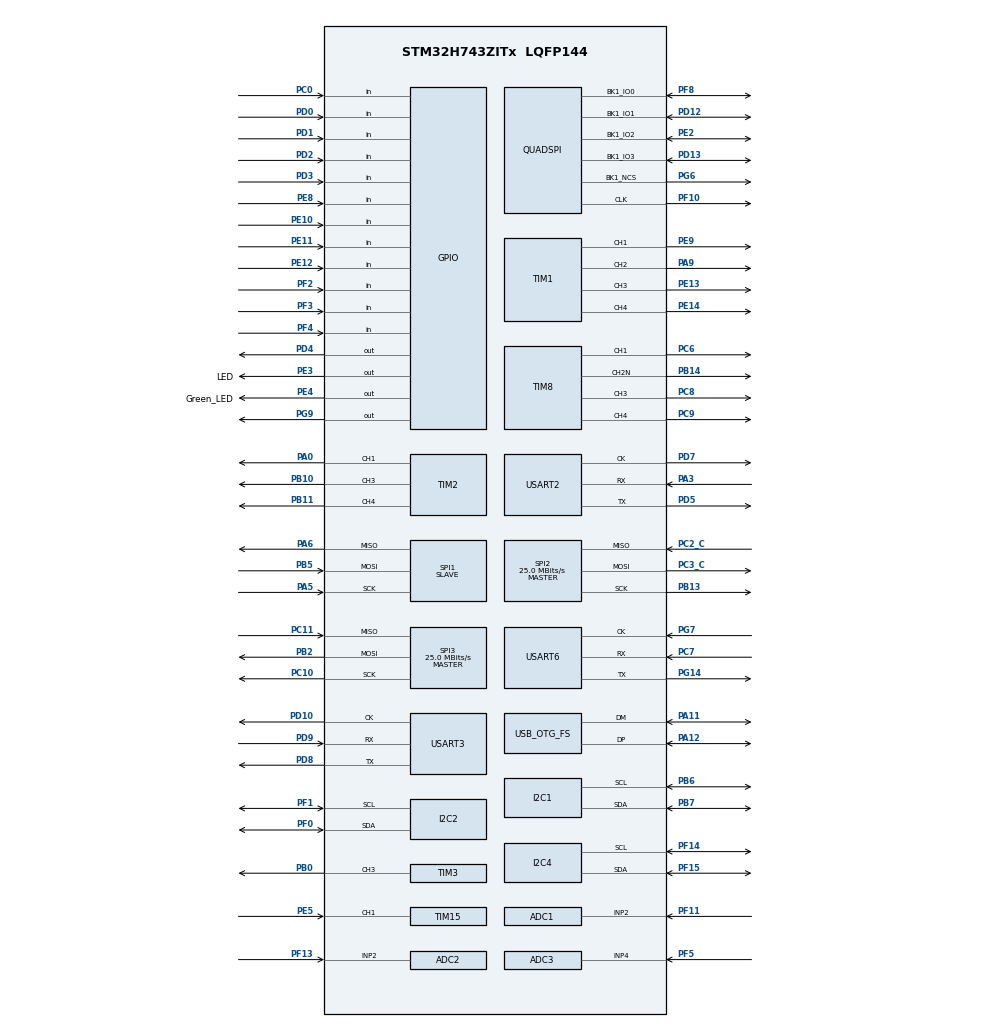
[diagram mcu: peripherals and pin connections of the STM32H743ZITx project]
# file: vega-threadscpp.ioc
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ADC1.Channel-1\#ChannelRegularConversion=ADC_CHANNEL_2
ADC1.ClockPrescaler=ADC_CLOCK_ASYNC_DIV4
ADC1.NbrOfConversionFlag=1
ADC1.OffsetNumber-1\#ChannelRegularConversion=ADC_OFFSET_NONE
ADC1.OffsetSignedSaturation-1\#ChannelRegularConversion=DISABLE
ADC1.Rank-1\#ChannelRegularConversion=1
ADC1.SamplingTime-1\#ChannelRegularConversion=ADC_SAMPLETIME_1CYCLE_5
ADC1.master=1
ADC2.Channel-0\#ChannelRegularConversion=ADC_CHANNEL_2
ADC2.ClockPrescaler=ADC_CLOCK_ASYNC_DIV4
ADC2.NbrOfConversionFlag=1
ADC2.OffsetNumber-0\#ChannelRegularConversion=ADC_OFFSET_NONE
ADC2.OffsetSignedSaturation-0\#ChannelRegularConversion=DISABLE
ADC2.Rank-0\#ChannelRegularConversion=1
ADC2.SamplingTime-0\#ChannelRegularConversion=ADC_SAMPLETIME_1CYCLE_5
ADC3.Channel-3\#ChannelRegularConversion=ADC_CHANNEL_4
ADC3.ClockPrescaler=ADC_CLOCK_ASYNC_DIV4
ADC3.NbrOfConversionFlag=1
ADC3.OffsetNumber-3\#ChannelRegularConversion=ADC_OFFSET_NONE
ADC3.OffsetSignedSaturation-3\#ChannelRegularConversion=DISABLE
ADC3.Rank-3\#ChannelRegularConversion=1
ADC3.SamplingTime-3\#ChannelRegularConversion=ADC_SAMPLETIME_1CYCLE_5
CORTEX_M7.default_mode_Activation=1
FREERTOS.Tasks01=blink01,24,128,StartBlink01,Default,NULL,Dynamic,NULL,NULL;blink02,16,128,StartBlink02,Default,NULL,Dynamic,NULL,NULL
FREERTOS.configENABLE_FPU=1
FREERTOS.configTOTAL_HEAP_SIZE=49152
FREERTOS.configUSE_NEWLIB_REENTRANT=1
I2C1.Timing=0x00707CBB
I2C2.Timing=0x00707CBB
I2C4.Timing=0x00707CBB
Mcu.Family=STM32H7
Mcu.Name=STM32H743ZITx
Mcu.Package=LQFP144
NVIC.OTG_FS_IRQn=true\:5\:0\:false\:false\:true\:true\:false\:true\:true
NVIC.PriorityGroup=NVIC_PRIORITYGROUP_4
NVIC.TIM6_DAC_IRQn=true\:15\:0\:false\:false\:true\:false\:false\:true\:true
NVIC.TimeBase=TIM6_DAC_IRQn
NVIC.TimeBaseIP=TIM6
PA0.Signal=S_TIM2_CH1_ETR
PA11.Mode=Device_Only
PA11.Signal=USB_OTG_FS_DM
PA12.Mode=Device_Only
PA12.Signal=USB_OTG_FS_DP
PA13\ (JTMS/SWDIO).Signal=DEBUG_JTMS-SWDIO
PA14\ (JTCK/SWCLK).Signal=DEBUG_JTCK-SWCLK
PA15\ (JTDI).Signal=SPI3_NSS
PA3.Mode=Synchronous
PA3.Signal=USART2_RX
PA4.Signal=SPI1_NSS
PA5.Mode=Full_Duplex_Slave
PA5.Signal=SPI1_SCK
PA6.Mode=Full_Duplex_Slave
PA6.Signal=SPI1_MISO
PA9.Signal=S_TIM1_CH2
PB0.Signal=S_TIM3_CH3
PB10.Signal=S_TIM2_CH3
PB11.Signal=S_TIM2_CH4
PB13.Mode=Full_Duplex_Master
PB13.Signal=SPI2_SCK
PB14.Mode=PWM Generation2 CH2N
PB14.Signal=TIM8_CH2N
PB2.Mode=Full_Duplex_Master
PB2.Signal=SPI3_MOSI
PB3\ (JTDO/TRACESWO).Signal=DEBUG_JTDO-SWO
PB4\ (NJTRST).Signal=DEBUG_JTRST
PB5.Mode=Full_Duplex_Slave
PB5.Signal=SPI1_MOSI
PB6.Mode=I2C
PB6.Signal=I2C1_SCL
PB7.Mode=I2C
PB7.Signal=I2C1_SDA
PB9.Signal=SPI2_NSS
PC0.Signal=GPIO_Input
PC10.Mode=Full_Duplex_Master
PC10.Signal=SPI3_SCK
PC11.Mode=Full_Duplex_Master
PC11.Signal=SPI3_MISO
PC14-OSC32_IN\ (OSC32_IN).Mode=LSE-External-Oscillator
PC14-OSC32_IN\ (OSC32_IN).Signal=RCC_OSC32_IN
PC15-OSC32_OUT\ (OSC32_OUT).Mode=LSE-External-Oscillator
PC15-OSC32_OUT\ (OSC32_OUT).Signal=RCC_OSC32_OUT
PC2_C.Mode=Full_Duplex_Master
PC2_C.Signal=SPI2_MISO
PC3_C.Mode=Full_Duplex_Master
PC3_C.Signal=SPI2_MOSI
PC6.Signal=S_TIM8_CH1
PC7.Mode=Synchronous Slave
PC7.Signal=USART6_RX
PC8.Signal=S_TIM8_CH3
PC9.Signal=S_TIM8_CH4
PD0.Signal=GPIO_Input
PD1.Signal=GPIO_Input
PD10.Mode=Synchronous
PD10.Signal=USART3_CK
PD12.Mode=Single Bank 1
PD12.Signal=QUADSPI_BK1_IO1
PD13.Mode=Single Bank 1
PD13.Signal=QUADSPI_BK1_IO3
PD2.Signal=GPIO_Input
PD3.Signal=GPIO_Input
PD4.Signal=GPIO_Output
PD5.Mode=Synchronous
PD5.Signal=USART2_TX
PD7.Mode=Synchronous
PD7.Signal=USART2_CK
PD8.Mode=Synchronous
PD8.Signal=USART3_TX
PD9.Mode=Synchronous
PD9.Signal=USART3_RX
PE10.Signal=GPIO_Input
PE11.Signal=GPIO_Input
PE12.Signal=GPIO_Input
PE13.Signal=S_TIM1_CH3
PE14.Signal=S_TIM1_CH4
PE2.Mode=Single Bank 1
PE2.Signal=QUADSPI_BK1_IO2
PE3.GPIO_Label=LED
PE3.Signal=GPIO_Output
PE4.GPIO_Label=Green_LED
PE4.Signal=GPIO_Output
PE5.Signal=S_TIM15_CH1
PE8.Signal=GPIO_Input
PE9.Signal=S_TIM1_CH1
PF0.Mode=I2C
PF0.Signal=I2C2_SDA
PF1.Mode=I2C
PF1.Signal=I2C2_SCL
PF10.Mode=Single Bank 1
PF10.Signal=QUADSPI_CLK
PF11.Mode=IN2-Single-Ended
PF11.Signal=ADC1_INP2
PF13.Mode=IN2-Single-Ended
PF13.Signal=ADC2_INP2
PF14.Mode=I2C
PF14.Signal=I2C4_SCL
PF15.Mode=I2C
PF15.Signal=I2C4_SDA
PF2.Signal=GPIO_Input
PF3.Signal=GPIO_Input
PF4.Signal=GPIO_Input
PF5.Mode=IN4-Single-Ended
PF5.Signal=ADC3_INP4
PF8.Mode=Single Bank 1
PF8.Signal=QUADSPI_BK1_IO0
PG11.Signal=ETH_TX_EN
PG14.Mode=Synchronous Slave
PG14.Signal=USART6_TX
PG6.Mode=Single Bank 1
PG6.Signal=QUADSPI_BK1_NCS
PG7.Mode=Synchronous Slave
PG7.Signal=USART6_CK
PG9.Signal=GPIO_Output
PH0-OSC_IN\ (PH0).Mode=HSE-External-Oscillator
PH0-OSC_IN\ (PH0).Signal=RCC_OSC_IN
PH1-OSC_OUT\ (PH1).Mode=HSE-External-Oscillator
PH1-OSC_OUT\ (PH1).Signal=RCC_OSC_OUT
ProjectManager.HeapSize=0x200
ProjectManager.StackSize=0x400
ProjectManager.TargetToolchain=STM32CubeIDE
RCC.ADCFreq_Value=75000000
RCC.APB1Freq_Value=32000000
RCC.APB2Freq_Value=32000000
RCC.APB3Freq_Value=64000000
RCC.APB4Freq_Value=32000000
RCC.CortexFreq_Value=64000000
RCC.D2PPRE1=RCC_APB1_DIV2
RCC.D2PPRE2=RCC_APB2_DIV2
RCC.D3PPRE=RCC_APB4_DIV2
RCC.DIVM1=2
RCC.DIVM2=2
RCC.DIVN1=12
RCC.DIVN2=12
RCC.DIVQ1=3
RCC.HCLKFreq_Value=64000000
RCC.PLL2FRACN=0
RCC.PLL3FRACN=0
RCC.PLLFRACN=0
RCC.PLLSourceVirtual=RCC_PLLSOURCE_HSE
RCC.SYSCLKFreq_VALUE=64000000
RCC.USBCLockSelection=RCC_USBCLKSOURCE_HSI48
RCC.USBFreq_Value=48000000
SH.S_TIM15_CH1.0=TIM15_CH1,Input_Capture1_from_TI1
SH.S_TIM1_CH1.0=TIM1_CH1,PWM Generation1 CH1
SH.S_TIM1_CH2.0=TIM1_CH2,PWM Generation2 CH2
SH.S_TIM1_CH3.0=TIM1_CH3,PWM Generation3 CH3
SH.S_TIM1_CH4.0=TIM1_CH4,PWM Generation4 CH4
SH.S_TIM2_CH1_ETR.0=TIM2_CH1,PWM Generation1 CH1
SH.S_TIM2_CH3.0=TIM2_CH3,PWM Generation3 CH3
SH.S_TIM2_CH4.0=TIM2_CH4,PWM Generation4 CH4
SH.S_TIM3_CH3.0=TIM3_CH3,PWM Generation3 CH3
SH.S_TIM8_CH1.0=TIM8_CH1,PWM Generation1 CH1
SH.S_TIM8_CH3.0=TIM8_CH3,PWM Generation3 CH3
SH.S_TIM8_CH4.0=TIM8_CH4,PWM Generation4 CH4
SPI1.Direction=SPI_DIRECTION_2LINES
SPI1.Mode=SPI_MODE_SLAVE
SPI1.VirtualType=VM_SLAVE
SPI2.CalculateBaudRate=25.0 MBits/s
SPI2.Direction=SPI_DIRECTION_2LINES
SPI2.Mode=SPI_MODE_MASTER
SPI2.VirtualType=VM_MASTER
SPI3.CalculateBaudRate=25.0 MBits/s
SPI3.Direction=SPI_DIRECTION_2LINES
SPI3.Mode=SPI_MODE_MASTER
SPI3.VirtualType=VM_MASTER
TIM1.Channel-PWM\ Generation1\ CH1=TIM_CHANNEL_1
TIM1.Channel-PWM\ Generation2\ CH2=TIM_CHANNEL_2
TIM1.Channel-PWM\ Generation3\ CH3=TIM_CHANNEL_3
TIM1.Channel-PWM\ Generation4\ CH4=TIM_CHANNEL_4
TIM15.Channel-Input_Capture1_from_TI1=TIM_CHANNEL_1
TIM15.TIM_MasterOutputTrigger=TIM_TRGO_UPDATE
TIM2.Channel-PWM\ Generation1\ CH1=TIM_CHANNEL_1
TIM2.Channel-PWM\ Generation3\ CH3=TIM_CHANNEL_3
TIM2.Channel-PWM\ Generation4\ CH4=TIM_CHANNEL_4
TIM3.Channel-PWM\ Generation3\ CH3=TIM_CHANNEL_3
TIM8.Channel-PWM\ Generation1\ CH1=TIM_CHANNEL_1
TIM8.Channel-PWM\ Generation2\ CH2N=TIM_CHANNEL_2
TIM8.Channel-PWM\ Generation3\ CH3=TIM_CHANNEL_3
TIM8.Channel-PWM\ Generation4\ CH4=TIM_CHANNEL_4
USART2.VirtualMode-Synchronous=VM_SYNC
USART3.VirtualMode-Synchronous=VM_SYNC
USART6.VirtualMode-Synchronous\ Slave=VM_SYNC
USB_DEVICE.CLASS_NAME_FS=CDC
USB_DEVICE.VirtualMode-CDC_FS=Cdc
USB_DEVICE.VirtualModeFS=Cdc_FS
USB_OTG_FS.VirtualMode=Device_Only
VP_FREERTOS_VS_CMSIS_V2.Mode=CMSIS_V2
VP_MEMORYMAP_VS_MEMORYMAP.Mode=CurAppReg
VP_SYS_VS_tim6.Mode=TIM6
VP_TIM15_VS_ClockSourceINT.Mode=Internal
VP_USB_DEVICE_VS_USB_DEVICE_CDC_FS.Mode=CDC_FS
board=custom

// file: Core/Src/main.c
/* USER CODE BEGIN Header */
/**
  ******************************************************************************
  * @file           : main.c
  * @brief          : Main program body
  ******************************************************************************
  * @attention
  *
  * Copyright (c) 2025 STMicroelectronics.
  * All rights reserved.
  *
  * This software is licensed under terms that can be found in the LICENSE file
  * in the root directory of this software component.
  * If no LICENSE file comes with this software, it is provided AS-IS.
  *
  ******************************************************************************
  */
/* USER CODE END Header */
#include "main.h"
#include "cmsis_os.h"
#include "adc.h"
#include "i2c.h"
#include "quadspi.h"
#include "spi.h"
#include "tim.h"
#include "usart.h"
#include "usb_device.h"
#include "gpio.h"

void SystemClock_Config(void);
void PeriphCommonClock_Config(void);
static void MPU_Config(void);
void MX_FREERTOS_Init(void);

/* USER CODE BEGIN 0 */
#ifdef __cplusplus
extern "C" {
#endif
void StartBlinkyThread(void);
void StartBlinky600LowerThread(void);
#ifdef __cplusplus
}
#endif
/* USER CODE END 0 */

int main(void)
{

  /* MPU Configuration--------------------------------------------------------*/
  MPU_Config();

  /* MCU Configuration--------------------------------------------------------*/

  /* Reset of all peripherals, Initializes the Flash interface and the Systick. */
  HAL_Init();

  /* Configure the system clock */
  SystemClock_Config();

  /* Configure the peripherals common clocks */
  PeriphCommonClock_Config();

  /* Initialize all configured peripherals */
  MX_GPIO_Init();
  MX_I2C1_Init();
  MX_I2C2_Init();
  MX_SPI1_Init();
  MX_SPI2_Init();
  MX_SPI3_Init();
  MX_USART2_Init();
  MX_USART3_Init();
  MX_USART6_Init();
  MX_QUADSPI_Init();
  MX_ADC1_Init();
  MX_ADC2_Init();
  MX_ADC3_Init();
  MX_TIM1_Init();
  MX_TIM2_Init();
  MX_TIM8_Init();
  MX_TIM15_Init();
  MX_I2C4_Init();
  MX_TIM3_Init();

  /* Init scheduler */
  osKernelInitialize();  /* Call init function for freertos objects (in cmsis_os2.c) */
  MX_FREERTOS_Init();

  /* Start scheduler */
  osKernelStart();

  /* We should never get here as control is now taken by the scheduler */

  /* Infinite loop */
  while (1)
  {

  }
}

void SystemClock_Config(void)
{
  RCC_OscInitTypeDef RCC_OscInitStruct = {0};
  RCC_ClkInitTypeDef RCC_ClkInitStruct = {0};

  /** Supply configuration update enable
  */
  HAL_PWREx_ConfigSupply(PWR_LDO_SUPPLY);

  /** Configure the main internal regulator output voltage
  */
  __HAL_PWR_VOLTAGESCALING_CONFIG(PWR_REGULATOR_VOLTAGE_SCALE3);

  while(!__HAL_PWR_GET_FLAG(PWR_FLAG_VOSRDY)) {}

  /** Initializes the RCC Oscillators according to the specified parameters
  * in the RCC_OscInitTypeDef structure.
  */
  RCC_OscInitStruct.OscillatorType = RCC_OSCILLATORTYPE_HSI48|RCC_OSCILLATORTYPE_HSI
                              |RCC_OSCILLATORTYPE_HSE;
  RCC_OscInitStruct.HSEState = RCC_HSE_ON;
  RCC_OscInitStruct.HSIState = RCC_HSI_DIV1;
  RCC_OscInitStruct.HSICalibrationValue = RCC_HSICALIBRATION_DEFAULT;
  RCC_OscInitStruct.HSI48State = RCC_HSI48_ON;
  RCC_OscInitStruct.PLL.PLLState = RCC_PLL_ON;
  RCC_OscInitStruct.PLL.PLLSource = RCC_PLLSOURCE_HSE;
  RCC_OscInitStruct.PLL.PLLM = 2;
  RCC_OscInitStruct.PLL.PLLN = 12;
  RCC_OscInitStruct.PLL.PLLP = 2;
  RCC_OscInitStruct.PLL.PLLQ = 3;
  RCC_OscInitStruct.PLL.PLLR = 2;
  RCC_OscInitStruct.PLL.PLLRGE = RCC_PLL1VCIRANGE_3;
  RCC_OscInitStruct.PLL.PLLVCOSEL = RCC_PLL1VCOMEDIUM;
  RCC_OscInitStruct.PLL.PLLFRACN = 0;
  if (HAL_RCC_OscConfig(&RCC_OscInitStruct) != HAL_OK)
  {
    Error_Handler();
  }

  /** Initializes the CPU, AHB and APB buses clocks
  */
  RCC_ClkInitStruct.ClockType = RCC_CLOCKTYPE_HCLK|RCC_CLOCKTYPE_SYSCLK
                              |RCC_CLOCKTYPE_PCLK1|RCC_CLOCKTYPE_PCLK2
                              |RCC_CLOCKTYPE_D3PCLK1|RCC_CLOCKTYPE_D1PCLK1;
  RCC_ClkInitStruct.SYSCLKSource = RCC_SYSCLKSOURCE_HSI;
  RCC_ClkInitStruct.SYSCLKDivider = RCC_SYSCLK_DIV1;
  RCC_ClkInitStruct.AHBCLKDivider = RCC_HCLK_DIV1;
  RCC_ClkInitStruct.APB3CLKDivider = RCC_APB3_DIV1;
  RCC_ClkInitStruct.APB1CLKDivider = RCC_APB1_DIV2;
  RCC_ClkInitStruct.APB2CLKDivider = RCC_APB2_DIV2;
  RCC_ClkInitStruct.APB4CLKDivider = RCC_APB4_DIV2;

  if (HAL_RCC_ClockConfig(&RCC_ClkInitStruct, FLASH_LATENCY_1) != HAL_OK)
  {
    Error_Handler();
  }
}

void PeriphCommonClock_Config(void)
{
  RCC_PeriphCLKInitTypeDef PeriphClkInitStruct = {0};

  /** Initializes the peripherals clock
  */
  PeriphClkInitStruct.PeriphClockSelection = RCC_PERIPHCLK_ADC;
  PeriphClkInitStruct.PLL2.PLL2M = 2;
  PeriphClkInitStruct.PLL2.PLL2N = 12;
  PeriphClkInitStruct.PLL2.PLL2P = 2;
  PeriphClkInitStruct.PLL2.PLL2Q = 2;
  PeriphClkInitStruct.PLL2.PLL2R = 2;
  PeriphClkInitStruct.PLL2.PLL2RGE = RCC_PLL2VCIRANGE_3;
  PeriphClkInitStruct.PLL2.PLL2VCOSEL = RCC_PLL2VCOMEDIUM;
  PeriphClkInitStruct.PLL2.PLL2FRACN = 0;
  PeriphClkInitStruct.AdcClockSelection = RCC_ADCCLKSOURCE_PLL2;
  if (HAL_RCCEx_PeriphCLKConfig(&PeriphClkInitStruct) != HAL_OK)
  {
    Error_Handler();
  }
}

 /* MPU Configuration */

void MPU_Config(void)
{
  MPU_Region_InitTypeDef MPU_InitStruct = {0};

  /* Disables the MPU */
  HAL_MPU_Disable();

  /** Initializes and configures the Region and the memory to be protected
  */
  MPU_InitStruct.Enable = MPU_REGION_ENABLE;
  MPU_InitStruct.Number = MPU_REGION_NUMBER0;
  MPU_InitStruct.BaseAddress = 0x0;
  MPU_InitStruct.Size = MPU_REGION_SIZE_4GB;
  MPU_InitStruct.SubRegionDisable = 0x87;
  MPU_InitStruct.TypeExtField = MPU_TEX_LEVEL0;
  MPU_InitStruct.AccessPermission = MPU_REGION_NO_ACCESS;
  MPU_InitStruct.DisableExec = MPU_INSTRUCTION_ACCESS_DISABLE;
  MPU_InitStruct.IsShareable = MPU_ACCESS_SHAREABLE;
  MPU_InitStruct.IsCacheable = MPU_ACCESS_NOT_CACHEABLE;
  MPU_InitStruct.IsBufferable = MPU_ACCESS_NOT_BUFFERABLE;

  HAL_MPU_ConfigRegion(&MPU_InitStruct);
  /* Enables the MPU */
  HAL_MPU_Enable(MPU_PRIVILEGED_DEFAULT);

}

void HAL_TIM_PeriodElapsedCallback(TIM_HandleTypeDef *htim)
{
  if (htim->Instance == TIM6)
  {
    HAL_IncTick();
  }
}

void Error_Handler(void)
{
  __disable_irq();
  while (1)
  {
  }
}

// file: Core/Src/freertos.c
/* USER CODE BEGIN Header */
/**
  ******************************************************************************
  * File Name          : freertos.c
  * Description        : Code for freertos applications
  ******************************************************************************
  * @attention
  *
  * Copyright (c) 2025 STMicroelectronics.
  * All rights reserved.
  *
  * This software is licensed under terms that can be found in the LICENSE file
  * in the root directory of this software component.
  * If no LICENSE file comes with this software, it is provided AS-IS.
  *
  ******************************************************************************
  */
/* USER CODE END Header */

#include "FreeRTOS.h"
#include "task.h"
#include "main.h"
#include "cmsis_os.h"

/* Definitions for blink01 */
osThreadId_t blink01Handle;
const osThreadAttr_t blink01_attributes = {
  .name = "blink01",
  .stack_size = 128 * 4,
  .priority = (osPriority_t) osPriorityNormal,
};
/* Definitions for blink02 */
osThreadId_t blink02Handle;
const osThreadAttr_t blink02_attributes = {
  .name = "blink02",
  .stack_size = 128 * 4,
  .priority = (osPriority_t) osPriorityBelowNormal,
};

void StartBlink01(void *argument);
void StartBlink02(void *argument);

extern void MX_USB_DEVICE_Init(void);
void MX_FREERTOS_Init(void); /* (MISRA C 2004 rule 8.1) */

void MX_FREERTOS_Init(void) {
  /* USER CODE BEGIN Init */
	 MX_USB_DEVICE_Init();
	 InterfaceSystemInit();
  /* USER CODE END Init */

  /* Create the thread(s) */
  /* creation of blink01 */
  blink01Handle = osThreadNew(StartBlink01, NULL, &blink01_attributes);

  /* creation of blink02 */
  blink02Handle = osThreadNew(StartBlink02, NULL, &blink02_attributes);

}

void StartBlink01(void *argument)
{
  /* init code for USB_DEVICE */
  MX_USB_DEVICE_Init();
  for(;;)
  {
    osDelay(1);
  }
}

void StartBlink02(void *argument)
{
  for(;;)
  {
    osDelay(1);
  }
}
